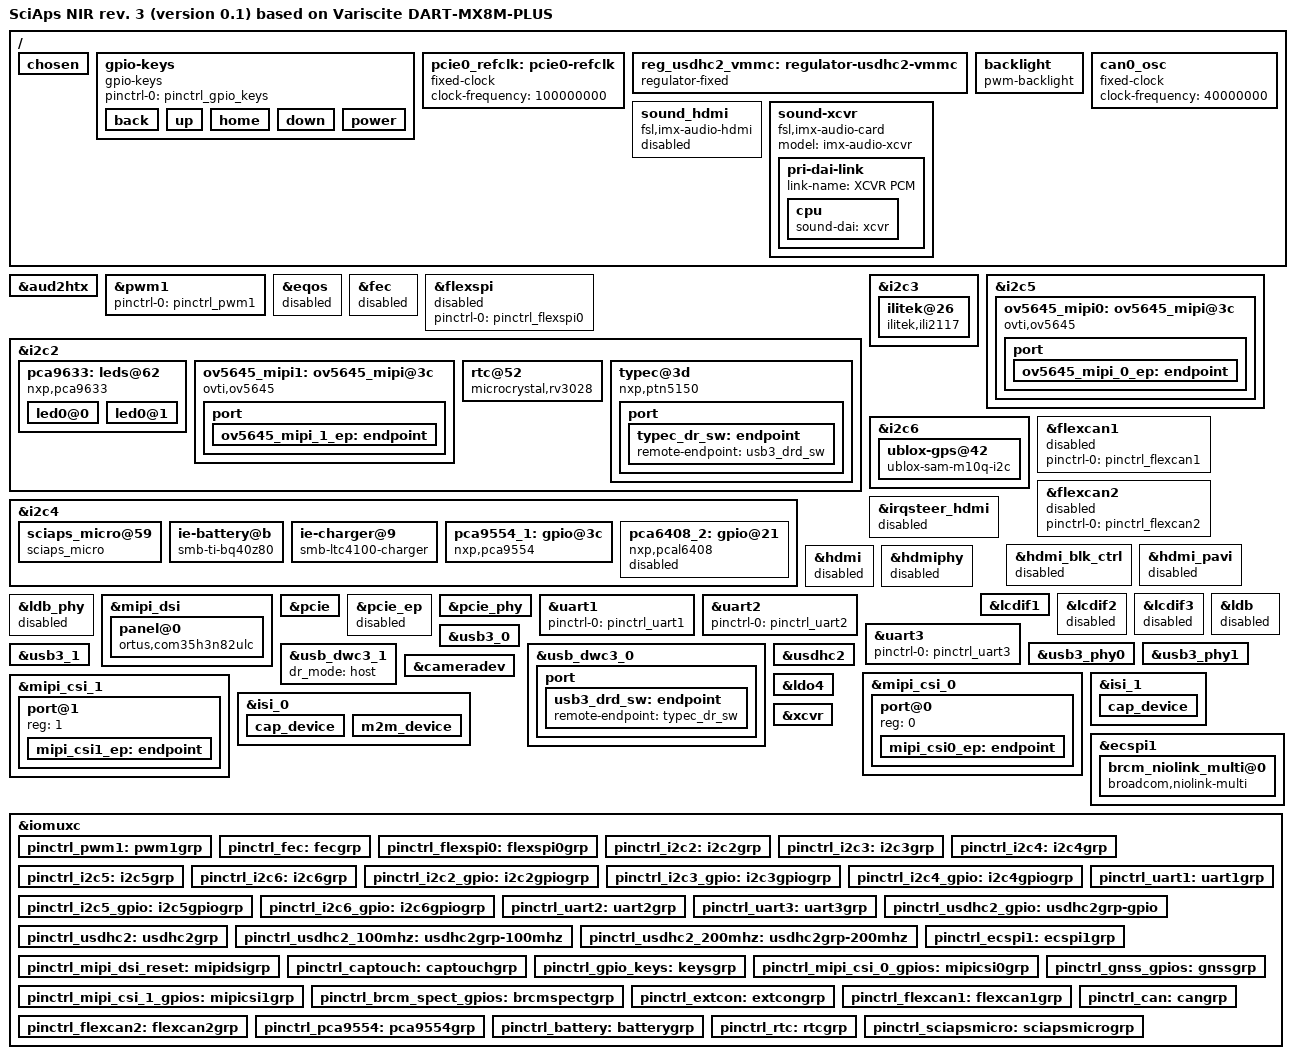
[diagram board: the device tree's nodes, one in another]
// SPDX-License-Identifier: (GPL-2.0+ OR MIT)
/*
 * Copyright 2019 NXP
 * Copyright 2020-2023 Variscite Ltd.
 * Copyright 2025 SciAps
 */

#include "imx8mp-var-dart.dtsi"

/ {
	model = "SciAps NIR rev. 3 (version 0.1) based on Variscite DART-MX8M-PLUS";
	chosen {
		stdout-path = &uart1;
		bootargs-append = "androidboot.primary_display=imx-drm moal.mod_para=wifi_mod_para_sd8987.conf";
	};

	gpio-keys {
		compatible = "gpio-keys";
		pinctrl-names = "default";
		pinctrl-0 = <&pinctrl_gpio_keys>;
		status = "okay";

		back {
			label = "Back";
			linux,code = <KEY_BACK>;
			gpios = <&pca9554_1 0 GPIO_ACTIVE_LOW>;
			wakeup-source;
		};

		up {
			label = "Up";
			linux,code = <KEY_UP>;
			gpios = <&pca9554_1 1 GPIO_ACTIVE_LOW>;
			wakeup-source;
		};

		home {
			label = "Home";
			linux,code = <KEY_HOMEPAGE>;
			gpios = <&pca9554_1 3 GPIO_ACTIVE_LOW>;
			wakeup-source;
		};

		down {
			label = "Down";
			linux,code = <KEY_DOWN>;
			gpios = <&pca9554_1 2 GPIO_ACTIVE_LOW>;
			wakeup-source;
		};

		power {
			label = "onoff-button";
			linux,code = <KEY_POWER>;
			gpios = <&gpio1 20 GPIO_ACTIVE_LOW>;
			interrupt-parent = <&gpio1>;
			interrupts = <20 IRQ_TYPE_EDGE_FALLING>;
			wakeup-source;
		};

/*
		touch {
			label = "wakeup";
			linux,code = <KEY_WAKEUP>; // KEY_SLEEP
			gpios = <&gpio1 17 GPIO_ACTIVE_HIGH>;
			interrupt-parent = <&gpio1>;
			interrupts = <17 IRQ_TYPE_EDGE_RISING>;
			wakeup-source;
			wakeup-event-action = <1>;
			debounce-interval = <0>;
		};
*/
	};

//	gpio-leds {
//		compatible = "gpio-leds";
//		pinctrl-names = "default";
//		pinctrl-0 = <&pinctrl_gpio_leds>;
//		status = "okay";
//
//		emmc {
//			label = "eMMC";
//			gpios = <&gpio4 18 GPIO_ACTIVE_HIGH>;
//			linux,default-trigger = "mmc2";
//		};
//	};

	pcie0_refclk: pcie0-refclk {
		compatible = "fixed-clock";
		#clock-cells = <0>;
		clock-frequency = <100000000>;
	};

	reg_usdhc2_vmmc: regulator-usdhc2-vmmc {
		compatible = "regulator-fixed";
		regulator-name = "VSD_3V3";
		regulator-min-microvolt = <3300000>;
		regulator-max-microvolt = <3300000>;
		gpio = <&gpio2 19 GPIO_ACTIVE_HIGH>;
		enable-active-high;
		startup-delay-us = <100>;
		off-on-delay-us = <12000>;
	};

	backlight: backlight {
		compatible = "pwm-backlight";
		pwms = <&pwm1 0 5000000 0>;
		status = "okay";

		brightness-levels = < 0  1  2  3  4  5  6  7  8  9
				     10 11 12 13 14 15 16 17 18 19
				     20 21 22 23 24 25 26 27 28 29
				     30 31 32 33 34 35 36 37 38 39
				     40 41 42 43 44 45 46 47 48 49
				     50 51 52 53 54 55 56 57 58 59
				     60 61 62 63 64 65 66 67 68 69
				     70 71 72 73 74 75 76 77 78 79
				     80 81 82 83 84 85 86 87 88 89
				     90 91 92 93 94 95 96 97 98 99
				    100>;
		default-brightness-level = <80>;
	};
	can0_osc: can0_osc {
		compatible = "fixed-clock";
		#clock-cells = <0>;
		clock-frequency = <40000000>;
	};

	sound_hdmi: sound_hdmi {
		compatible = "fsl,imx-audio-hdmi";
		model = "audio-hdmi";
		audio-cpu = <&aud2htx>;
		hdmi-out;
		constraint-rate = <44100>,
				<88200>,
				<176400>,
				<32000>,
				<48000>,
				<96000>,
				<192000>;
		status = "disabled";
	};

	sound-xcvr {
		compatible = "fsl,imx-audio-card";
		model = "imx-audio-xcvr";
		pri-dai-link {
			link-name = "XCVR PCM";
			cpu {
				sound-dai = <&xcvr>;
			};
		};
	};
};

&aud2htx {
	status = "okay";
};

&pwm1 {
	pinctrl-names = "default";
	pinctrl-0 = <&pinctrl_pwm1>;
	status = "okay";
};


&eqos {
	status = "disabled";
};

&fec {
	status = "disabled";
};

&flexspi {
	pinctrl-names = "default";
	pinctrl-0 = <&pinctrl_flexspi0>;
	status = "disabled";
};


// sciaps micro i2c-4
// ilitek i2c-3
&i2c2 {
	clock-frequency = <400000>;
	pinctrl-names = "default", "gpio";
	pinctrl-0 = <&pinctrl_i2c2>;
	pinctrl-1 = <&pinctrl_i2c2_gpio>;
	scl-gpios = <&gpio5 16 GPIO_ACTIVE_HIGH>;
	sda-gpios = <&gpio5 17 GPIO_ACTIVE_HIGH>;
	status = "okay";

	pca9633: leds@62 {
		compatible = "nxp,pca9633";
        #address-cells = <1>;
        #size-cells = <0>;
		#gpio-controller;
        reg = <0x62>;
        //nxp,totem-pole;
        //nxp,change-on-ack;
		status = "okay";

        led0@0 {
            label = "nose-cam-0";
			reg = <0>;
			linux,default-trigger = "none";
		};
		led0@1 {
			label = "nose-cam-1";
			reg = <1>;
			linux,default-trigger = "none";
		};
	};

	ov5645_mipi1: ov5645_mipi@3c {
		compatible = "ovti,ov5645";
		reg = <0x3c>;
		pinctrl-names = "default";
		pinctrl-0 = <&pinctrl_mipi_csi_1_gpios>;
#if 0
		// Disabled as the board uses its own oscillator.
		clocks = <&clk IMX8MP_CLK_IPP_DO_CLKO2>;
		clock-names = "xclk";
		assigned-clocks = <&clk IMX8MP_CLK_IPP_DO_CLKO2>;
		assigned-clock-parents = <&clk IMX8MP_CLK_24M>;
		clock-frequency = <24000000>;
		mclk = <24000000>;
		mclk_source = <0>;
#endif
		assigned-clock-rates = <24000000>;
		csi_id = <1>;
		enable-gpios = <&gpio3 9 GPIO_ACTIVE_HIGH>;
		reset-gpios = <&gpio3 6 GPIO_ACTIVE_LOW>;
		mclk-enable-gpios = <&gpio3 8 GPIO_ACTIVE_HIGH>;
		external-power-supplies;
		mipi_csi;
		status = "okay";

		port {
			ov5645_mipi_1_ep: endpoint {
				remote-endpoint = <&mipi_csi1_ep>;
				data-lanes = <1 2>;
				clock-lanes = <0>;
			};
		};
	};

	/* RV3028 RTC module */
	rtc@52 {
		compatible = "microcrystal,rv3028";
		reg = <0x52>;
		trickle-resistor-ohms = <3000>;
		backup-switchover-mode = <1>;
		//pinctrl-names = "default";
		//pinctrl-0 = <&pinctrl_rtc>;
		//interrupt-parent = <&gpio5>;
		//interrupts = <4 IRQ_TYPE_EDGE_FALLING>;
		//wakeup-source;
		status = "okay";
	};


	typec@3d {
		compatible = "nxp,ptn5150";
		pinctrl-names = "default";
		pinctrl-0 = <&pinctrl_extcon>;
		reg = <0x3d>;
		interrupt-parent = <&gpio1>;
		interrupts = <10 IRQ_TYPE_LEVEL_HIGH>;
		irq-is-id-quirk;
		status ="okay";

		port {
			typec_dr_sw: endpoint {
				remote-endpoint = <&usb3_drd_sw>;
			};
		};
	};
};

&i2c3 {
	clock-frequency = <400000>;
	pinctrl-names = "default", "gpio";
	pinctrl-0 = <&pinctrl_i2c3>;
	pinctrl-1 = <&pinctrl_i2c3_gpio>;
	scl-gpios = <&gpio5 18 GPIO_ACTIVE_HIGH>;
	sda-gpios = <&gpio5 19 GPIO_ACTIVE_HIGH>;
	status = "okay";

	ilitek@26 {
		compatible = "ilitek,ili2117";
		reg = <0x26>;
		// -- interrupt-parent = <&msm_gpio>;
		// -- interrupts = <13 0x0>;
		//vdd-supply = <&pm8916_l17>;
		//vcc_i2c-supply = <&pm8916_l6>;
		// -- touch,irq-gpio = <&msm_gpio 13 0x0>;
		// -- touch,reset-gpio = <&msm_gpio 12 0x0>;
		//ilitek,vbus = "vcc_i2c";
		//ilitek,vdd = "vdd";
		// -- ilitek,name = "ilitek_i2c";
		pinctrl-names = "default";
		pinctrl-0 = <&pinctrl_captouch>;
		reset-gpios = <&gpio4 25 GPIO_ACTIVE_LOW>;
		interrupt-parent = <&gpio1>;
		interrupts = <21 IRQ_TYPE_EDGE_RISING>;// IRQ_TYPE_EDGE_RISING IRQ_TYPE_EDGE_FALLING
		touchscreen-size-x = <480>;
		touchscreen-size-y = <640>;
		//ili2117a,poll-period = <1>;
		//touchscreen-inverted-x;
		//touchscreen-inverted-y;
		wakeup-source;
		status = "ok";
	};

};

/*



*/
&i2c4 {
	clock-frequency = <100000>;
	pinctrl-names = "default", "gpio";
	pinctrl-0 = <&pinctrl_i2c4>;
	pinctrl-1 = <&pinctrl_i2c4_gpio>;
	scl-gpios = <&gpio5 20 GPIO_ACTIVE_HIGH>;
	sda-gpios = <&gpio5 21 GPIO_ACTIVE_HIGH>;
	status = "okay";

	sciaps_micro@59 {
		compatible = "sciaps_micro";
		reg = <0x59>;
		pinctrl-names = "default";
		pinctrl-0 = <&pinctrl_sciapsmicro>;
		sciaps-trigger-gpio = <&gpio1 9 GPIO_ACTIVE_LOW>;
		smart-battery-comm-enable-gpio = <&pca9554_1 4 GPIO_ACTIVE_HIGH>;
		status = "okay";
	};

	ie-battery@b {
		compatible = "smb-ti-bq40z80";
		reg = <0xb>;
		pinctrl-names = "default";
		pinctrl-0 = <&pinctrl_battery>;
		sciaps,support-shutdown = <1>;
		sciaps,shutdown-timer   = <12>;
		sciaps,capacity-low-thres-mAh = <10>;
		sciaps,capacity-low-thres = <5>; // 0.5 %
		sciaps,voltage-crit-low-thres-mV = <11000>;
		sciaps,voltage-low-thres-mV = <14000>;
		sciaps,charging-current-mA = <1700>;
		sciaps,poll-interval = <10>; // seconds
		sciaps,poll-slow-enable-count = <6>; // # Number of retries before entering slow polling mode: ~60 s on 10 seconds interval
		sciaps,poll-interval-slow = <60>; //seconds
		sciaps-scap-npfo-gpio = <&gpio1 0 GPIO_ACTIVE_HIGH>;
		status = "okay";
	};

	ie-charger@9 {
		compatible = "smb-ltc4100-charger";
		reg = <0x9>;
		sciaps,poll-interval = <2>; // seconds
		sciaps,poll-slow-enable-count = <30>; // # Number of retries before entering slow polling mode: ~60 s on 2 seconds interval
		sciaps,poll-interval-slow = <2>; //seconds - slow mode  is the same as we need to detect quickly when the charger gets plugged in
		status = "okay";
	};

	pca9554_1: gpio@3c {
		compatible = "nxp,pca9554";
		standard-regs-fallback;
		reg = <0x3c>;
		gpio-controller;
		#gpio-cells = <2>;
		pinctrl-names = "default";
		pinctrl-0 = <&pinctrl_pca9554>;
		interrupt-parent = <&gpio1>;
		interrupts = <5 IRQ_TYPE_EDGE_FALLING>;
		status = "okay";
	};

	pca6408_2: gpio@21 {
		compatible = "nxp,pcal6408";
		standard-regs-fallback;
		reg = <0x21>;
		gpio-controller;
		#gpio-cells = <2>;
		status = "disabled";
	};

};

&i2c5 {
	clock-frequency = <400000>;
	pinctrl-names = "default", "gpio";
	pinctrl-0 = <&pinctrl_i2c5>;
	pinctrl-1 = <&pinctrl_i2c5_gpio>;
	scl-gpios = <&gpio3 21 GPIO_ACTIVE_HIGH>;
	sda-gpios = <&gpio3 25 GPIO_ACTIVE_HIGH>;
	status = "okay";

	ov5645_mipi0: ov5645_mipi@3c {
		compatible = "ovti,ov5645";
		reg = <0x3c>;
		pinctrl-names = "default";
		pinctrl-0 = <&pinctrl_mipi_csi_0_gpios>;
#if 0
		// Disabled as the board uses its own oscillator.
		clocks = <&clk IMX8MP_CLK_IPP_DO_CLKO2>;
		clock-names = "xclk";
		assigned-clocks = <&clk IMX8MP_CLK_IPP_DO_CLKO2>;
		assigned-clock-parents = <&clk IMX8MP_CLK_24M>;
		clock-frequency = <24000000>;
		mclk = <24000000>;
		mclk_source = <0>;
#endif
		assigned-clock-rates = <24000000>;
		csi_id = <0>;
		enable-gpios = <&gpio3 7 GPIO_ACTIVE_HIGH>;
		reset-gpios = <&gpio3 1 GPIO_ACTIVE_LOW>;
		mclk-enable-gpios = <&gpio3 14 GPIO_ACTIVE_HIGH>;
		mipi_csi;
		auto-focus;
		external-power-supplies;
		status = "okay";

		port {
			ov5645_mipi_0_ep: endpoint {
				remote-endpoint = <&mipi_csi0_ep>;
				data-lanes = <1 2>;
				clock-lanes = <0>;
			};
		};
	};
};



&i2c6 {
	clock-frequency = <400000>;
	pinctrl-names = "default", "gpio";
	pinctrl-0 = <&pinctrl_i2c6>;
	pinctrl-1 = <&pinctrl_i2c6_gpio>;
	scl-gpios = <&gpio3 28 GPIO_ACTIVE_HIGH>;
	sda-gpios = <&gpio3 29 GPIO_ACTIVE_HIGH>;
	status = "okay";

	ublox-gps@42 {
		compatible = "ublox-sam-m10q-i2c";
		reg = <0x42>;
		pinctrl-names = "default";
		pinctrl-0 = <&pinctrl_gnss_gpios>;
		ubx,hAccRejectHardThreshold     = <35000>;  // mm
		ubx,pDOPRejectHardThreshold     = <3000>;   // 0.01
		ubx,pDOPRejectThreshold         = <1000>;   // 0.01
		ubx,hAccAcceptThreshold         = <15000>;  // mm
		ubx,nSatsAcceptAlwaysThreshold  = <5>;      // # of sats
		extint-gpios = <&gpio3 26 GPIO_ACTIVE_LOW>;
		reset-gpios = <&gpio3 27 GPIO_ACTIVE_LOW>;
		status = "okay";
	};
};

&flexcan1 {
	pinctrl-names = "default";
	pinctrl-0 = <&pinctrl_flexcan1>;
	status = "disbaled";
};

&flexcan2 {
	pinctrl-names = "default";
	pinctrl-0 = <&pinctrl_flexcan2>;
	status = "disabled";
};

&irqsteer_hdmi {
	status = "disabled";
};

&hdmi_blk_ctrl {
	status = "disabled";
};

&hdmi_pavi {
	status = "disabled";
};

&hdmi {
	status = "disabled";
};

&hdmiphy {
	status = "disabled";
};

/* MIPI-DSI */
&lcdif1 {
	status = "okay";
};

/* LVDS */
&lcdif2 {
	status = "disabled";
};

/* HDMI */
&lcdif3 {
	status = "disabled";
	thres-low  = <1 2>;             /* (FIFO * 1 / 2) */
	thres-high = <3 4>;             /* (FIFO * 3 / 4) */
};

&ldb {
	status = "disabled";
};

&ldb_phy {
	status = "disabled";
};

&mipi_dsi {
	status = "okay";
	panel@0 {
		compatible = "ortus,com35h3n82ulc";
		backlight = <&backlight>;
		reg = <0>;
		pinctrl-0 = <&pinctrl_mipi_dsi_reset>;
		reset-gpios = <&gpio1 6 GPIO_ACTIVE_LOW>;
		dsi-lanes = <2>;
		video-mode = <2>;	/* 0: burst mode
					 * 1: non-burst mode with sync event
					 * 2: non-burst mode with sync pulse
					 */
		status = "okay";
	};
};

&pcie {
	reset-gpio = <&pca6408_2 3 GPIO_ACTIVE_LOW>;
	ext_osc = <1>;
	clocks = <&clk IMX8MP_CLK_HSIO_ROOT>,
		 <&clk IMX8MP_CLK_PCIE_AUX>,
		 <&clk IMX8MP_CLK_HSIO_AXI>,
		 <&clk IMX8MP_CLK_PCIE_ROOT>;
	clock-names = "pcie", "pcie_aux", "pcie_phy", "pcie_bus";
	assigned-clocks = <&clk IMX8MP_CLK_HSIO_AXI>,
			  <&clk IMX8MP_CLK_PCIE_AUX>;
	assigned-clock-rates = <500000000>, <10000000>;
	assigned-clock-parents = <&clk IMX8MP_SYS_PLL2_500M>,
				 <&clk IMX8MP_SYS_PLL2_50M>;
	l1ss-disabled;
	status = "okay";
};

&pcie_ep {
	ext_osc = <1>;
	clocks = <&clk IMX8MP_CLK_HSIO_ROOT>,
		 <&clk IMX8MP_CLK_PCIE_AUX>,
		 <&clk IMX8MP_CLK_HSIO_AXI>,
		 <&clk IMX8MP_CLK_PCIE_ROOT>;
	clock-names = "pcie", "pcie_aux", "pcie_phy", "pcie_bus";
	assigned-clocks = <&clk IMX8MP_CLK_HSIO_AXI>,
			  <&clk IMX8MP_CLK_PCIE_AUX>;
	assigned-clock-rates = <500000000>, <10000000>;
	assigned-clock-parents = <&clk IMX8MP_SYS_PLL2_500M>,
				 <&clk IMX8MP_SYS_PLL2_50M>;
	status = "disabled";
};

&pcie_phy {
	fsl,refclk-pad-mode = <IMX8_PCIE_REFCLK_PAD_INPUT>;
	clocks = <&pcie0_refclk>;
	clock-names = "ref";
	status = "okay";
};

/* Console */
&uart1 {
	pinctrl-names = "default";
	pinctrl-0 = <&pinctrl_uart1>;
	status = "okay";
};

/* Header */
&uart2 {
	pinctrl-names = "default";
	pinctrl-0 = <&pinctrl_uart2>;
	status = "okay";
};

/* Header */
&uart3 {
	pinctrl-names = "default";
	pinctrl-0 = <&pinctrl_uart3>;
	status = "okay";
};

&usb3_phy0 {
	fsl,phy-tx-vref-tune = <0xe>;
	fsl,phy-tx-preemp-amp-tune = <3>;
	fsl,phy-tx-vboost-level = <5>;
	fsl,phy-comp-dis-tune = <7>;
	fsl,pcs-tx-deemph-3p5db = <0x21>;
	fsl,phy-pcs-tx-swing-full = <0x7f>;
	status = "okay";
};

&usb3_0 {
	status = "okay";
};

&usb_dwc3_0 {
	dr_mode = "otg";
	hnp-disable;
	srp-disable;
	adp-disable;
	usb-role-switch;
	role-switch-default-mode = "none";
	snps,dis-u1-entry-quirk;
	snps,dis-u2-entry-quirk;
	status = "okay";

	port {
		usb3_drd_sw: endpoint {
			remote-endpoint = <&typec_dr_sw>;
		};
	};
};

&usb3_phy1 {
	fsl,phy-tx-preemp-amp-tune = <3>;
	fsl,phy-tx-vref-tune = <0xb>;
	status = "okay";
};

&usb3_1 {
	status = "okay";
};

&usb_dwc3_1 {
	dr_mode = "host";
	status = "okay";
};

&usdhc2 {
	pinctrl-names = "default", "state_100mhz", "state_200mhz";
	pinctrl-0 = <&pinctrl_usdhc2>, <&pinctrl_usdhc2_gpio>;
	pinctrl-1 = <&pinctrl_usdhc2_100mhz>, <&pinctrl_usdhc2_gpio>;
	pinctrl-2 = <&pinctrl_usdhc2_200mhz>, <&pinctrl_usdhc2_gpio>;
	cd-gpios = <&gpio2 12 GPIO_ACTIVE_LOW>;
	vmmc-supply = <&reg_usdhc2_vmmc>;
	bus-width = <4>;
	status = "okay";
};

&mipi_csi_0 {
	#address-cells = <1>;
	#size-cells = <0>;
	status = "okay";
	clock-frequency = <266000000>;
	assigned-clock-parents = <&clk IMX8MP_SYS_PLL1_266M>;
	assigned-clock-rates = <266000000>;

	port@0 {
		reg = <0>;
		mipi_csi0_ep: endpoint {
			remote-endpoint = <&ov5645_mipi_0_ep>;
			data-lanes = <2>;
			//csis-hs-settle = <13>;
			//csis-clk-settle = <2>;
			csis-hs-settle = <5>;
			csis-wclk;
		};
	};
};

&mipi_csi_1 {
	#address-cells = <1>;
	#size-cells = <0>;
	status = "okay";

	port@1 {
		reg = <1>;
		mipi_csi1_ep: endpoint {
			remote-endpoint = <&ov5645_mipi_1_ep>;
			data-lanes = <2>;
			//csis-hs-settle = <13>;
			//csis-clk-settle = <2>;
			csis-hs-settle = <5>;
			csis-wclk;
		};
	};
};

&cameradev {
	status = "okay";
};

&isi_0 {
	status = "okay";

	cap_device {
		status = "okay";
	};

	m2m_device {
		status = "okay";
	};
};

&isi_1 {
	status = "okay";

	cap_device {
		status = "okay";
	};
};

&ecspi1 {
	pinctrl-names = "default";
	pinctrl-0 = <&pinctrl_ecspi1>;
	cs-gpios = <&gpio5  9 GPIO_ACTIVE_LOW>;
	status = "okay";

    brcm_niolink_multi@0 {
        compatible = "broadcom,niolink-multi";
        reg = <0>;
		pinctrl-names = "default";
		pinctrl-0 = <&pinctrl_brcm_spect_gpios>;
		enable-gpios = <&gpio4 22 GPIO_ACTIVE_HIGH>;  //It is actually DPP_nUART_SPI
		cs-gpios = <&gpio1 17 GPIO_ACTIVE_LOW>, <&gpio4 24 GPIO_ACTIVE_LOW>,  <&gpio4 23 GPIO_ACTIVE_LOW>;    //GPIO117/CS_GPIO, DPP_UART_SEL_nPROG, SOM_DPP_JTAG_EN
		spi-cs-gpios = <&gpio1 29 GPIO_ACTIVE_LOW>;
		//interrupt-parent = <&gpio1>;
		//interrupts = <29 IRQ_TYPE_EDGE_BOTH>;
		//interrup t-controller;
		//#interrupt-cells = <1>;
        spi-max-frequency = <12000000>;
        spi-cpha = <1>;
        spi-cpol = <0>;
		brcm,nir2-cooling-temp-C = <0xc1200000>;
        status = "okay";
    };

};

&ldo4 {
	regulator-min-microvolt = <1800000>;
	regulator-max-microvolt = <1800000>;
};

&xcvr {
	#sound-dai-cells = <0>;
	status = "okay";
};

&iomuxc {
	//pinctrl-names = "default";
	//pinctrl-0 = <&pinctrl_hog>;

	//pinctrl_hog: hoggrp {
	//	fsl,pins = <
	//		MX8MP_IOMUXC_HDMI_DDC_SCL__HDMIMIX_HDMI_SCL			0x400001c2
	//		MX8MP_IOMUXC_HDMI_DDC_SDA__HDMIMIX_HDMI_SDA			0x400001c2
	//		MX8MP_IOMUXC_HDMI_HPD__HDMIMIX_HDMI_HPD				0x40000010
	//		MX8MP_IOMUXC_HDMI_CEC__HDMIMIX_HDMI_CEC				0x40000010
	//	>;
	//};

	pinctrl_pwm1: pwm1grp {
		fsl,pins = <
			MX8MP_IOMUXC_GPIO1_IO01__PWM1_OUT				0x116
		>;
	};

	pinctrl_fec: fecgrp {
		fsl,pins = <
			MX8MP_IOMUXC_SAI1_RXD4__ENET1_RGMII_RD0				0x90
			MX8MP_IOMUXC_SAI1_RXD5__ENET1_RGMII_RD1				0x90
			MX8MP_IOMUXC_SAI1_RXD6__ENET1_RGMII_RD2				0x90
			MX8MP_IOMUXC_SAI1_RXD7__ENET1_RGMII_RD3				0x90
			MX8MP_IOMUXC_SAI1_TXC__ENET1_RGMII_RXC				0x90
			MX8MP_IOMUXC_SAI1_TXFS__ENET1_RGMII_RX_CTL			0x90
			MX8MP_IOMUXC_SAI1_TXD0__ENET1_RGMII_TD0				0x00
			MX8MP_IOMUXC_SAI1_TXD1__ENET1_RGMII_TD1				0x00
			MX8MP_IOMUXC_SAI1_TXD2__ENET1_RGMII_TD2				0x00
			MX8MP_IOMUXC_SAI1_TXD3__ENET1_RGMII_TD3				0x00
			MX8MP_IOMUXC_SAI1_TXD4__ENET1_RGMII_TX_CTL			0x00
			MX8MP_IOMUXC_SAI1_TXD5__ENET1_RGMII_TXC				0x00
		>;
	};

	pinctrl_flexspi0: flexspi0grp {
		fsl,pins = <
			MX8MP_IOMUXC_NAND_ALE__FLEXSPI_A_SCLK				0x1c2
			MX8MP_IOMUXC_NAND_CE0_B__FLEXSPI_A_SS0_B			0x82
			MX8MP_IOMUXC_NAND_DATA00__FLEXSPI_A_DATA00			0x82
			MX8MP_IOMUXC_NAND_DATA01__FLEXSPI_A_DATA01			0x82
			MX8MP_IOMUXC_NAND_DATA02__FLEXSPI_A_DATA02			0x82
			MX8MP_IOMUXC_NAND_DATA03__FLEXSPI_A_DATA03			0x82
		>;
	};

	pinctrl_i2c2: i2c2grp {
		fsl,pins = <
			MX8MP_IOMUXC_I2C2_SCL__I2C2_SCL					0x400001c2
			MX8MP_IOMUXC_I2C2_SDA__I2C2_SDA					0x400001c2
		>;
	};

	pinctrl_i2c3: i2c3grp {
		fsl,pins = <
			MX8MP_IOMUXC_I2C3_SCL__I2C3_SCL					0x400001c2
			MX8MP_IOMUXC_I2C3_SDA__I2C3_SDA					0x400001c2
		>;
	};

	pinctrl_i2c4: i2c4grp {
		fsl,pins = <
			MX8MP_IOMUXC_I2C4_SCL__I2C4_SCL					0x400001c2
			MX8MP_IOMUXC_I2C4_SDA__I2C4_SDA					0x400001c2
		>;
	};

	pinctrl_i2c5: i2c5grp {
		fsl,pins = <
			MX8MP_IOMUXC_SAI5_RXD0__I2C5_SCL				0x400001c2
			MX8MP_IOMUXC_SAI5_MCLK__I2C5_SDA				0x400001c2
		>;
	};

	pinctrl_i2c6: i2c6grp {
		fsl,pins = <
			MX8MP_IOMUXC_HDMI_CEC__I2C6_SCL					0x400001c2
			MX8MP_IOMUXC_HDMI_HPD__I2C6_SDA					0x400001c2
		>;
	};

	pinctrl_i2c2_gpio: i2c2gpiogrp {
		fsl,pins = <
			MX8MP_IOMUXC_I2C2_SCL__GPIO5_IO16				0x1c2
			MX8MP_IOMUXC_I2C2_SDA__GPIO5_IO17				0x1c2
		>;
	};

	pinctrl_i2c3_gpio: i2c3gpiogrp {
		fsl,pins = <
			MX8MP_IOMUXC_I2C3_SCL__GPIO5_IO18				0x1c2
			MX8MP_IOMUXC_I2C3_SDA__GPIO5_IO19				0x1c2
		>;
	};

	pinctrl_i2c4_gpio: i2c4gpiogrp {
		fsl,pins = <
			MX8MP_IOMUXC_I2C4_SCL__GPIO5_IO20				0x1c2
			MX8MP_IOMUXC_I2C4_SDA__GPIO5_IO21				0x1c2
		>;
	};

	pinctrl_i2c5_gpio: i2c5gpiogrp {
		fsl,pins = <
			MX8MP_IOMUXC_SAI5_RXD0__I2C5_SCL				0x1c2
			MX8MP_IOMUXC_SAI5_MCLK__I2C5_SDA				0x1c2
		>;
	};

	pinctrl_i2c6_gpio: i2c6gpiogrp {
		fsl,pins = <
			MX8MP_IOMUXC_HDMI_CEC__I2C6_SCL				0x1c2
			MX8MP_IOMUXC_HDMI_HPD__I2C6_SDA				0x1c2
		>;
	};

	pinctrl_uart1: uart1grp {
		fsl,pins = <
			MX8MP_IOMUXC_UART1_RXD__UART1_DCE_RX				0x40
			MX8MP_IOMUXC_UART1_TXD__UART1_DCE_TX				0x40
		>;
	};

	pinctrl_uart2: uart2grp {
		fsl,pins = <
			MX8MP_IOMUXC_UART2_RXD__UART2_DCE_RX				0x40
			MX8MP_IOMUXC_UART2_TXD__UART2_DCE_TX				0x40
		>;
	};

	pinctrl_uart3: uart3grp {
		fsl,pins = <
			MX8MP_IOMUXC_UART3_RXD__UART3_DCE_RX				0x40
			MX8MP_IOMUXC_UART3_TXD__UART3_DCE_TX				0x40
		>;
	};

	pinctrl_usdhc2_gpio: usdhc2grp-gpio {
		fsl,pins = <
			MX8MP_IOMUXC_SD2_CD_B__GPIO2_IO12				0x1c4
			MX8MP_IOMUXC_SD2_RESET_B__GPIO2_IO19				0x40
		>;
	};

	pinctrl_usdhc2: usdhc2grp {
		fsl,pins = <
			MX8MP_IOMUXC_SD2_CLK__USDHC2_CLK				0x190
			MX8MP_IOMUXC_SD2_CMD__USDHC2_CMD				0x1d0
			MX8MP_IOMUXC_SD2_DATA0__USDHC2_DATA0				0x1d0
			MX8MP_IOMUXC_SD2_DATA1__USDHC2_DATA1				0x1d0
			MX8MP_IOMUXC_SD2_DATA2__USDHC2_DATA2				0x1d0
			MX8MP_IOMUXC_SD2_DATA3__USDHC2_DATA3				0x1d0
			MX8MP_IOMUXC_GPIO1_IO04__USDHC2_VSELECT				0xc0
		>;
	};

	pinctrl_usdhc2_100mhz: usdhc2grp-100mhz {
		fsl,pins = <
			MX8MP_IOMUXC_SD2_CLK__USDHC2_CLK				0x194
			MX8MP_IOMUXC_SD2_CMD__USDHC2_CMD				0x1d4
			MX8MP_IOMUXC_SD2_DATA0__USDHC2_DATA0				0x1d4
			MX8MP_IOMUXC_SD2_DATA1__USDHC2_DATA1				0x1d4
			MX8MP_IOMUXC_SD2_DATA2__USDHC2_DATA2				0x1d4
			MX8MP_IOMUXC_SD2_DATA3__USDHC2_DATA3				0x1d4
			MX8MP_IOMUXC_GPIO1_IO04__USDHC2_VSELECT				0xc0
		>;
	};

	pinctrl_usdhc2_200mhz: usdhc2grp-200mhz {
		fsl,pins = <
			MX8MP_IOMUXC_SD2_CLK__USDHC2_CLK				0x196
			MX8MP_IOMUXC_SD2_CMD__USDHC2_CMD				0x1d6
			MX8MP_IOMUXC_SD2_DATA0__USDHC2_DATA0				0x1d6
			MX8MP_IOMUXC_SD2_DATA1__USDHC2_DATA1				0x1d6
			MX8MP_IOMUXC_SD2_DATA2__USDHC2_DATA2				0x1d6
			MX8MP_IOMUXC_SD2_DATA3__USDHC2_DATA3				0x1d6
			MX8MP_IOMUXC_GPIO1_IO04__USDHC2_VSELECT				0xc0
		>;
	};

	pinctrl_ecspi1: ecspi1grp {
		fsl,pins = <
			MX8MP_IOMUXC_ECSPI1_SCLK__ECSPI1_SCLK				0x16
			MX8MP_IOMUXC_ECSPI1_MOSI__ECSPI1_MOSI				0x16
			MX8MP_IOMUXC_ECSPI1_MISO__ECSPI1_MISO				0x16
			MX8MP_IOMUXC_ECSPI1_SS0__GPIO5_IO09					0x16 // disable pullup//0x146 // SPI1_CS_PERIF: weak pullup enabled, drivestrength x6
		>;
	};

	pinctrl_mipi_dsi_reset: mipidsigrp {
		fsl,pins = <
			MX8MP_IOMUXC_GPIO1_IO06__GPIO1_IO06				0x16 // LCD nRst: pulled down on schematics , Fast slew rate, drivestrength x6
		>;
	};

	pinctrl_captouch: captouchgrp {
		fsl,pins = <
			MX8MP_IOMUXC_SAI2_TXC__GPIO4_IO25				0x16  // Touch nRst: weak pulldown enabled, drivestrength x6
			MX8MP_IOMUXC_ENET_TD0__GPIO1_IO21				0x16  // Touch nInt: weak pullup enabled, drivestrength x6
		>;
	};

	pinctrl_gpio_keys: keysgrp {
		fsl,pins = <
			MX8MP_IOMUXC_ENET_TD1__GPIO1_IO20				0x146 // ONOFF Button: weak pullup enabled, drivestrength x6
		>;
	};

	pinctrl_mipi_csi_0_gpios: mipicsi0grp {
		fsl,pins = <
			MX8MP_IOMUXC_NAND_CE0_B__GPIO3_IO01				0x16 // CSI1_RST: Fast slew rate, drivestrength x6
			MX8MP_IOMUXC_NAND_DATA01__GPIO3_IO07			0x16 // CSI1_PWDN: Fast slew rate, drivestrength x6
			MX8MP_IOMUXC_NAND_DQS__GPIO3_IO14				0x16 // CSI0_MCLK_EN: Fast slew rate, drivestrength x6
			//MX8MP_IOMUXC_NAND_DQS__GPIO3_IO14				0x146 // CSI0_MCLK_EN: weak pullup enabled, drivestrength x6
		>;
	};

	pinctrl_mipi_csi_1_gpios: mipicsi1grp {
		fsl,pins = <
			MX8MP_IOMUXC_NAND_DATA00__GPIO3_IO06			0x16 // CSI2_RST: Fast slew rate, drivestrength x6
			MX8MP_IOMUXC_NAND_DATA03__GPIO3_IO09			0x16 // CSI2_PWDN: Fast slew rate, drivestrength x6
			MX8MP_IOMUXC_NAND_DATA02__GPIO3_IO08			0x16 // CSI0_MCLK_EN: Fast slew rate, drivestrength x6
			//MX8MP_IOMUXC_NAND_DATA02__GPIO3_IO08			0x146 // CSI0_MCLK_EN: weak pullup enabled, drivestrength x6
		>;
	};

	pinctrl_gnss_gpios: gnssgrp {
		fsl,pins = <
			MX8MP_IOMUXC_HDMI_DDC_SCL__GPIO3_IO26			0x16 // GPS_EXTINT: Fast slew rate, drivestrength x6
			MX8MP_IOMUXC_HDMI_DDC_SDA__GPIO3_IO27			0x36 // GPS_nRST: Open Drain Enabled, Fast slew rate, drivestrength x6
		>;
	};

	pinctrl_brcm_spect_gpios: brcmspectgrp {
		fsl,pins = <
			MX8MP_IOMUXC_ENET_RD3__GPIO1_IO29				0x16 // Loop back SPI_nCS Interrupt: weak pullup enabled, Fast slew rate, drivestrength x6
			MX8MP_IOMUXC_ENET_MDIO__GPIO1_IO17				0x16 // GPIO117/CS_GPIO as nCS0: weak pullup enabled, Fast slew rate, drivestrength x6
			MX8MP_IOMUXC_SAI2_TXFS__GPIO4_IO24				0x16 // DPP_UART_SEL_nPROG as nCS1: weak pullup enabled, Fast slew rate, drivestrength x6
			MX8MP_IOMUXC_SAI2_RXD0__GPIO4_IO23				0x16 // SOM_DPP_JTAG_EN as nCS2: weak pullup enabled, Fast slew rate, drivestrength x6
			MX8MP_IOMUXC_SAI2_RXC__GPIO4_IO22				0x156 // DPP_nUART_SPI: weak pullup enabled, Fast slew rate, drivestrength x6
		>;
	};

	pinctrl_extcon: extcongrp {
		fsl,pins = <
			MX8MP_IOMUXC_GPIO1_IO10__GPIO1_IO10				0x10
		>;
	};

	pinctrl_flexcan1: flexcan1grp {
		fsl,pins = <
			MX8MP_IOMUXC_SAI2_RXC__CAN1_TX					0x154
			MX8MP_IOMUXC_SAI2_TXC__CAN1_RX					0x154
		>;
	};

	pinctrl_flexcan2: flexcan2grp {
		fsl,pins = <
			MX8MP_IOMUXC_SAI2_MCLK__CAN2_RX					0x154
			MX8MP_IOMUXC_SAI2_TXD0__CAN2_TX					0x154
		>;
	};

	pinctrl_can: cangrp {
		fsl,pins = <
			MX8MP_IOMUXC_GPIO1_IO06__GPIO1_IO06				0x1c6
			//-----MX8MP_IOMUXC_SPDIF_RX__GPIO5_IO04				0x16
		>;
	};

	pinctrl_pca9554: pca9554grp {
		fsl,pins = <
			MX8MP_IOMUXC_GPIO1_IO05__GPIO1_IO05				0x1c6
		>;
	};

	pinctrl_gpio_keys: keysgrp {
		fsl,pins = <
			MX8MP_IOMUXC_ENET_TD1__GPIO1_IO20				0x146 // ONOFF Button: weak pullup enabled, drivestrength x6
		>;
	};

	pinctrl_battery: batterygrp {
		fsl,pins = <
			MX8MP_IOMUXC_GPIO1_IO00__GPIO1_IO00				0x1c6
		>;
	};

	pinctrl_rtc: rtcgrp {
		fsl,pins = <
			MX8MP_IOMUXC_SPDIF_RX__GPIO5_IO04				0x1c0
		>;
	};

	pinctrl_sciapsmicro: sciapsmicrogrp {
		fsl,pins = <
			MX8MP_IOMUXC_GPIO1_IO09__GPIO1_IO09             0x146 // Trigger: weak pullup enabled, drivestrength x6
		>;
	};

};

#include "imx8mp-android.dtsi"
